# CM_CORE_AON__RTC register map
Vendor: Texas Instruments
Peripheral module from a debugger description file (folder DRA75x_DRA74x).
Registers are 32-bit, access per field, reset 0x0 unless marked. A register's access mark holds for its fields unless they carry their own. Offsets are as the file gives them; lines under a group give offsets from that group; [hi:lo] are bit positions; {n}, {i} and the like mark numbered series; 'fields as' and 'values as' point back to an identical list; <NAME> marks a mode.

## CM_CORE_AON__RTC
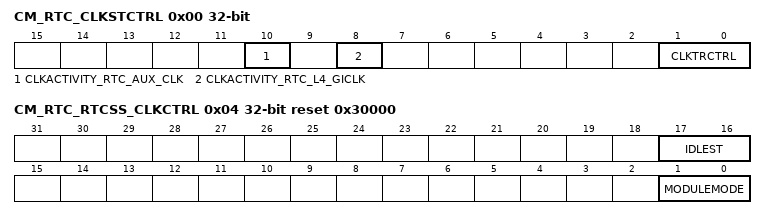
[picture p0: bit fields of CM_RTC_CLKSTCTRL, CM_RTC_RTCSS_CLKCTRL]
0x00 CM_RTC_CLKSTCTRL — This register enables the domain power state transition. It controls the HW supervised domain power state transition between ON-ACTIVE and ON-INACTIVE states. It also hold one status bit per clock input of the domain.
  [10] CLKACTIVITY_RTC_AUX_CLK ro — This field indicates the state of the RTC_AUX_CLK in the domain. [warm reset insensitive]
    0=INACT (Corresponding clock is definitely gated); 1=ACT (Corresponding clock is running or gating/ungating transition is on-going)
  [8] CLKACTIVITY_RTC_L4_GICLK ro — This field indicates the state of the RTC_L4_GICLK clock in the domain. [warm reset insensitive]
    values as CLKACTIVITY_RTC_AUX_CLK
  [1:0] CLKTRCTRL rw — Controls the clock state transition of the WKUPAON clock domain.
    0=NO_SLEEP (NO_SLEEP: Sleep transition cannot be initiated. Wakeup transition may however occur.); 2=SW_WKUP (SW_WKUP: Start a software forced wake-up transition on the domain.); 3=HW_AUTO (HW_AUTO: Automatic transition is enabled. Sleep and wakeup transition are based upon hardware conditions.)
0x04 CM_RTC_RTCSS_CLKCTRL reset 0x30000 — This register manages the RTC clocks.
  [17:16] IDLEST ro — Module idle status. [warm reset insensitive]
    0=FUNC (Module is fully functional, including OCP); 1=TRANS (Module is performing transition: wakeup, or sleep, or sleep abortion); 2=IDLE (Module is in Idle mode (only OCP part). It is functional if using separate functional clock); 3=DISABLE (Module is disabled and cannot be accessed)
  [1:0] MODULEMODE rw — Control the way mandatory clocks are managed.
    0=DISABLED (Module is disabled by SW. Any OCP access to module results in an error, except if resulting from a module wakeup (asynchronous wakeup).); 2=ENABLED (Module is explicitly enabled. Interface clock (if not used for functions) may be gated according to the clock domain state. Functional clocks are guarantied to stay present. As long as in this configuration, power domain sleep transition cannot happen.)
